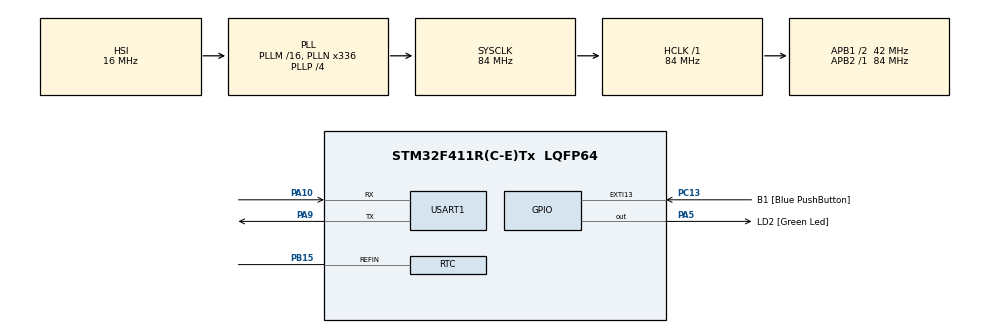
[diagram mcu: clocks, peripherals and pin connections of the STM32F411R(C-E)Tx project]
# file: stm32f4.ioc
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FREERTOS.Tasks01=defaultTask,0,128,StartDefaultTask,Default,NULL
Mcu.Family=STM32F4
Mcu.Name=STM32F411R(C-E)Tx
Mcu.Package=LQFP64
NVIC.PriorityGroup=NVIC_PRIORITYGROUP_4
NVIC.RTC_Alarm_IRQn=true\:5\:0\:false\:false\:true\:true\:true\:true
NVIC.RTC_WKUP_IRQn=true\:5\:0\:false\:false\:true\:true\:true\:true
PA10.Mode=Asynchronous
PA10.Signal=USART1_RX
PA13.GPIO_Label=TMS
PA13.Mode=Serial_Wire
PA13.Signal=SYS_JTMS-SWDIO
PA14.GPIO_Label=TCK
PA14.Mode=Serial_Wire
PA14.Signal=SYS_JTCK-SWCLK
PA2.GPIO_Label=USART_TX
PA2.Signal=USART2_TX
PA3.GPIO_Label=USART_RX
PA3.Signal=USART2_RX
PA5.GPIO_Label=LD2 [Green Led]
PA5.Signal=GPIO_Output
PA9.Mode=Asynchronous
PA9.Signal=USART1_TX
PB15.GPIO_Mode=GPIO_MODE_AF_PP
PB15.GPIO_Speed=GPIO_SPEED_FREQ_LOW
PB15.Mode=Reference_Clock_Detection_Activate
PB15.Signal=RTC_REFIN
PB3.GPIO_Label=SWO
PB3.Signal=SYS_JTDO-SWO
PC13-ANTI_TAMP.GPIO_Label=B1 [Blue PushButton]
PC13-ANTI_TAMP.GPIO_ModeDefaultEXTI=GPIO_MODE_IT_FALLING
PC13-ANTI_TAMP.Signal=GPXTI13
PC14-OSC32_IN.Mode=LSE-External-Oscillator
PC14-OSC32_IN.Signal=RCC_OSC32_IN
PC15-OSC32_OUT.Mode=LSE-External-Oscillator
PC15-OSC32_OUT.Signal=RCC_OSC32_OUT
PH0\ -\ OSC_IN.Mode=HSE-External-Clock-Source
PH0\ -\ OSC_IN.Signal=RCC_OSC_IN
PH1\ -\ OSC_OUT.Mode=HSE-External-Clock-Source
PH1\ -\ OSC_OUT.Signal=RCC_OSC_OUT
ProjectManager.HeapSize=0x200
ProjectManager.StackSize=0x400
ProjectManager.TargetToolchain=Makefile
RCC.48MHZClocksFreq_Value=84000000
RCC.AHBFreq_Value=84000000
RCC.APB1CLKDivider=RCC_HCLK_DIV2
RCC.APB1Freq_Value=42000000
RCC.APB1TimFreq_Value=84000000
RCC.APB2Freq_Value=84000000
RCC.APB2TimFreq_Value=84000000
RCC.CortexFreq_Value=84000000
RCC.FLatency-AdvancedSettings=FLASH_LATENCY_2
RCC.HCLKFreq_Value=84000000
RCC.HSE_VALUE=8000000
RCC.HSI_VALUE=16000000
RCC.PLLN=336
RCC.PLLP=RCC_PLLP_DIV4
RCC.SYSCLKFreq_VALUE=84000000
RCC.SYSCLKSource=RCC_SYSCLKSOURCE_PLLCLK
RCC.VCOOutputFreq_Value=336000000
RTC.Alarm=RTC_ALARM_A
RTC.Alarm_B=RTC_ALARM_B
USART1.VirtualMode=VM_ASYNC
VP_FREERTOS_VS_CMSIS_V1.Mode=CMSIS_V1
VP_RTC_VS_RTC_Activate.Mode=RTC_Enabled
VP_RTC_VS_RTC_Alarm_A_Intern.Mode=Alarm A
VP_RTC_VS_RTC_Alarm_B_Intern.Mode=Alarm B
VP_RTC_VS_RTC_Calendar.Mode=RTC_Calendar
VP_RTC_VS_RTC_WakeUp_intern.Mode=WakeUp
board=NUCLEO-F411RE

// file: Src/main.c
/* USER CODE BEGIN Header */
/**
  ******************************************************************************
  * @file           : main.c
  * @brief          : Main program body
  ******************************************************************************
  * @attention
  *
  * <h2><center>&copy; Copyright (c) 2020 STMicroelectronics.
  * All rights reserved.</center></h2>
  *
  * This software component is licensed by ST under Ultimate Liberty license
  * SLA0044, the "License"; You may not use this file except in compliance with
  * the License. You may obtain a copy of the License at:
  *                             www.st.com/SLA0044
  *
  ******************************************************************************
  */
/* USER CODE END Header */

#include "main.h"
#include "cmsis_os.h"
#include <stdio.h>

RTC_HandleTypeDef hrtc;

UART_HandleTypeDef huart1;

osThreadId defaultTaskHandle;

void SystemClock_Config(void);
static void MX_GPIO_Init(void);
static void MX_USART1_UART_Init(void);
static void MX_RTC_Init(void);
void StartDefaultTask(void const * argument);

int main(void)
{

  /* MCU Configuration--------------------------------------------------------*/

  /* Reset of all peripherals, Initializes the Flash interface and the Systick. */
  HAL_Init();

  /* Configure the system clock */
  SystemClock_Config();

  /* Initialize all configured peripherals */
  MX_GPIO_Init();
  MX_USART1_UART_Init();
  MX_RTC_Init();

  /* Create the thread(s) */
  /* definition and creation of defaultTask */
  osThreadDef(defaultTask, StartDefaultTask, osPriorityNormal, 0, 128);
  defaultTaskHandle = osThreadCreate(osThread(defaultTask), NULL);

  /* Start scheduler */
  osKernelStart();

  /* We should never get here as control is now taken by the scheduler */

  /* Infinite loop */
  while (1)
  {

  }
}

void SystemClock_Config(void)
{
  RCC_OscInitTypeDef RCC_OscInitStruct = {0};
  RCC_ClkInitTypeDef RCC_ClkInitStruct = {0};
  RCC_PeriphCLKInitTypeDef PeriphClkInitStruct = {0};

  /** Configure the main internal regulator output voltage
  */
  __HAL_RCC_PWR_CLK_ENABLE();
  __HAL_PWR_VOLTAGESCALING_CONFIG(PWR_REGULATOR_VOLTAGE_SCALE1);
  /** Initializes the CPU, AHB and APB busses clocks
  */
  RCC_OscInitStruct.OscillatorType = RCC_OSCILLATORTYPE_HSI|RCC_OSCILLATORTYPE_LSI;
  RCC_OscInitStruct.HSIState = RCC_HSI_ON;
  RCC_OscInitStruct.HSICalibrationValue = RCC_HSICALIBRATION_DEFAULT;
  RCC_OscInitStruct.LSIState = RCC_LSI_ON;
  RCC_OscInitStruct.PLL.PLLState = RCC_PLL_ON;
  RCC_OscInitStruct.PLL.PLLSource = RCC_PLLSOURCE_HSI;
  RCC_OscInitStruct.PLL.PLLM = 16;
  RCC_OscInitStruct.PLL.PLLN = 336;
  RCC_OscInitStruct.PLL.PLLP = RCC_PLLP_DIV4;
  RCC_OscInitStruct.PLL.PLLQ = 4;
  if (HAL_RCC_OscConfig(&RCC_OscInitStruct) != HAL_OK)
  {
    Error_Handler();
  }
  /** Initializes the CPU, AHB and APB busses clocks
  */
  RCC_ClkInitStruct.ClockType = RCC_CLOCKTYPE_HCLK|RCC_CLOCKTYPE_SYSCLK
                              |RCC_CLOCKTYPE_PCLK1|RCC_CLOCKTYPE_PCLK2;
  RCC_ClkInitStruct.SYSCLKSource = RCC_SYSCLKSOURCE_PLLCLK;
  RCC_ClkInitStruct.AHBCLKDivider = RCC_SYSCLK_DIV1;
  RCC_ClkInitStruct.APB1CLKDivider = RCC_HCLK_DIV2;
  RCC_ClkInitStruct.APB2CLKDivider = RCC_HCLK_DIV1;

  if (HAL_RCC_ClockConfig(&RCC_ClkInitStruct, FLASH_LATENCY_2) != HAL_OK)
  {
    Error_Handler();
  }
  PeriphClkInitStruct.PeriphClockSelection = RCC_PERIPHCLK_RTC;
  PeriphClkInitStruct.RTCClockSelection = RCC_RTCCLKSOURCE_LSI;
  if (HAL_RCCEx_PeriphCLKConfig(&PeriphClkInitStruct) != HAL_OK)
  {
    Error_Handler();
  }
}

static void MX_RTC_Init(void)
{

  RTC_TimeTypeDef sTime = {0};
  RTC_DateTypeDef sDate = {0};
  RTC_AlarmTypeDef sAlarm = {0};

  /** Initialize RTC Only
  */
  hrtc.Instance = RTC;
  hrtc.Init.HourFormat = RTC_HOURFORMAT_24;
  hrtc.Init.AsynchPrediv = 127;
  hrtc.Init.SynchPrediv = 255;
  hrtc.Init.OutPut = RTC_OUTPUT_DISABLE;
  hrtc.Init.OutPutPolarity = RTC_OUTPUT_POLARITY_HIGH;
  hrtc.Init.OutPutType = RTC_OUTPUT_TYPE_OPENDRAIN;
  if (HAL_RTC_Init(&hrtc) != HAL_OK)
  {
    Error_Handler();
  }

  /** Initialize RTC and set the Time and Date
  */
  sTime.Hours = 0x0;
  sTime.Minutes = 0x0;
  sTime.Seconds = 0x0;
  sTime.DayLightSaving = RTC_DAYLIGHTSAVING_NONE;
  sTime.StoreOperation = RTC_STOREOPERATION_RESET;
  if (HAL_RTC_SetTime(&hrtc, &sTime, RTC_FORMAT_BCD) != HAL_OK)
  {
    Error_Handler();
  }
  sDate.WeekDay = RTC_WEEKDAY_MONDAY;
  sDate.Month = RTC_MONTH_JANUARY;
  sDate.Date = 0x1;
  sDate.Year = 0x0;

  if (HAL_RTC_SetDate(&hrtc, &sDate, RTC_FORMAT_BCD) != HAL_OK)
  {
    Error_Handler();
  }
  /** Enable the Alarm A
  */
  sAlarm.AlarmTime.Hours = 0x0;
  sAlarm.AlarmTime.Minutes = 0x0;
  sAlarm.AlarmTime.Seconds = 0x0;
  sAlarm.AlarmTime.SubSeconds = 0x0;
  sAlarm.AlarmTime.DayLightSaving = RTC_DAYLIGHTSAVING_NONE;
  sAlarm.AlarmTime.StoreOperation = RTC_STOREOPERATION_RESET;
  sAlarm.AlarmMask = RTC_ALARMMASK_NONE;
  sAlarm.AlarmSubSecondMask = RTC_ALARMSUBSECONDMASK_ALL;
  sAlarm.AlarmDateWeekDaySel = RTC_ALARMDATEWEEKDAYSEL_DATE;
  sAlarm.AlarmDateWeekDay = 0x1;
  sAlarm.Alarm = RTC_ALARM_A;
  if (HAL_RTC_SetAlarm_IT(&hrtc, &sAlarm, RTC_FORMAT_BCD) != HAL_OK)
  {
    Error_Handler();
  }
  /** Enable the Alarm B
  */
  sAlarm.AlarmDateWeekDay = 0x1;
  sAlarm.Alarm = RTC_ALARM_B;
  if (HAL_RTC_SetAlarm_IT(&hrtc, &sAlarm, RTC_FORMAT_BCD) != HAL_OK)
  {
    Error_Handler();
  }
  /** Enable the WakeUp
  */
  if (HAL_RTCEx_SetWakeUpTimer_IT(&hrtc, 0, RTC_WAKEUPCLOCK_RTCCLK_DIV16) != HAL_OK)
  {
    Error_Handler();
  }
  /** Enable the reference Clock input
  */
  if (HAL_RTCEx_SetRefClock(&hrtc) != HAL_OK)
  {
    Error_Handler();
  }

}

static void MX_USART1_UART_Init(void)
{

  huart1.Instance = USART1;
  huart1.Init.BaudRate = 115200;
  huart1.Init.WordLength = UART_WORDLENGTH_8B;
  huart1.Init.StopBits = UART_STOPBITS_1;
  huart1.Init.Parity = UART_PARITY_NONE;
  huart1.Init.Mode = UART_MODE_TX_RX;
  huart1.Init.HwFlowCtl = UART_HWCONTROL_NONE;
  huart1.Init.OverSampling = UART_OVERSAMPLING_16;
  if (HAL_UART_Init(&huart1) != HAL_OK)
  {
    Error_Handler();
  }

}

static void MX_GPIO_Init(void)
{
  GPIO_InitTypeDef GPIO_InitStruct = {0};

  /* GPIO Ports Clock Enable */
  __HAL_RCC_GPIOC_CLK_ENABLE();
  __HAL_RCC_GPIOH_CLK_ENABLE();
  __HAL_RCC_GPIOA_CLK_ENABLE();
  __HAL_RCC_GPIOB_CLK_ENABLE();

  /*Configure GPIO pin Output Level */
  HAL_GPIO_WritePin(LD2_GPIO_Port, LD2_Pin, GPIO_PIN_RESET);

  /*Configure GPIO pin : B1_Pin */
  GPIO_InitStruct.Pin = B1_Pin;
  GPIO_InitStruct.Mode = GPIO_MODE_IT_FALLING;
  GPIO_InitStruct.Pull = GPIO_NOPULL;
  HAL_GPIO_Init(B1_GPIO_Port, &GPIO_InitStruct);

  /*Configure GPIO pins : USART_TX_Pin USART_RX_Pin */
  GPIO_InitStruct.Pin = USART_TX_Pin|USART_RX_Pin;
  GPIO_InitStruct.Mode = GPIO_MODE_AF_PP;
  GPIO_InitStruct.Pull = GPIO_NOPULL;
  GPIO_InitStruct.Speed = GPIO_SPEED_FREQ_VERY_HIGH;
  GPIO_InitStruct.Alternate = GPIO_AF7_USART2;
  HAL_GPIO_Init(GPIOA, &GPIO_InitStruct);

  /*Configure GPIO pin : LD2_Pin */
  GPIO_InitStruct.Pin = LD2_Pin;
  GPIO_InitStruct.Mode = GPIO_MODE_OUTPUT_PP;
  GPIO_InitStruct.Pull = GPIO_NOPULL;
  GPIO_InitStruct.Speed = GPIO_SPEED_FREQ_LOW;
  HAL_GPIO_Init(LD2_GPIO_Port, &GPIO_InitStruct);

}

void StartDefaultTask(void const * argument)
{

		RTC_TimeTypeDef currTime;
	RTC_DateTypeDef currDate;
	uint8_t sec[18] = {0};
	int i = 0;
  /* USER CODE BEGIN 5 */
  /* Infinite loop */
  for(;;)
  {
	HAL_RTC_GetTime(&hrtc, &currTime, RTC_FORMAT_BIN);
	HAL_RTC_GetDate(&hrtc, &currDate, RTC_FORMAT_BIN);
	i = i+1;
	sprintf((char*)sec, "TIME: %04d",currTime.SubSeconds);
	HAL_GPIO_TogglePin(GPIOA, GPIO_PIN_5);
	HAL_UART_Transmit(&huart1, (uint8_t *)"\033[2J", 4,1000);
	HAL_UART_Transmit(&huart1, (uint8_t *)"\033[0;0H", 6,1000);
	HAL_UART_Transmit(&huart1, sec, sizeof(sec), 1000);
    vTaskDelay(1000);
  }
  /* USER CODE END 5 */
}

void Error_Handler(void)
{
}

/************************ (C) COPYRIGHT STMicroelectronics *****END OF FILE****/
